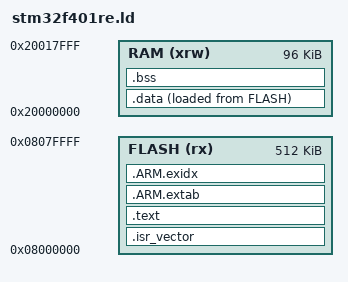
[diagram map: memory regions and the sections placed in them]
ENTRY(Reset_Handler)
MEMORY
{
  FLASH (rx)  : ORIGIN = 0x08000000, LENGTH = 512K
  RAM   (xrw) : ORIGIN = 0x20000000, LENGTH = 96K
}
_estack = ORIGIN(RAM) + LENGTH(RAM);
SECTIONS
{
  .isr_vector : { KEEP(*(.isr_vector)) } > FLASH
  .text : { *(.text*) *(.rodata*) KEEP(*(.init)) KEEP(*(.fini)) } > FLASH
  .ARM.extab : { *(.ARM.extab*) } > FLASH
  .ARM.exidx : { *(.ARM.exidx*) } > FLASH
  .data : { _sdata = .; *(.data*) _edata = .; } > RAM AT > FLASH
  _sidata = LOADADDR(.data);
  .bss (NOLOAD) : { _sbss = .; *(.bss*) *(COMMON) _ebss = .; } > RAM
  . = ALIGN(8);
  end = .;
}
